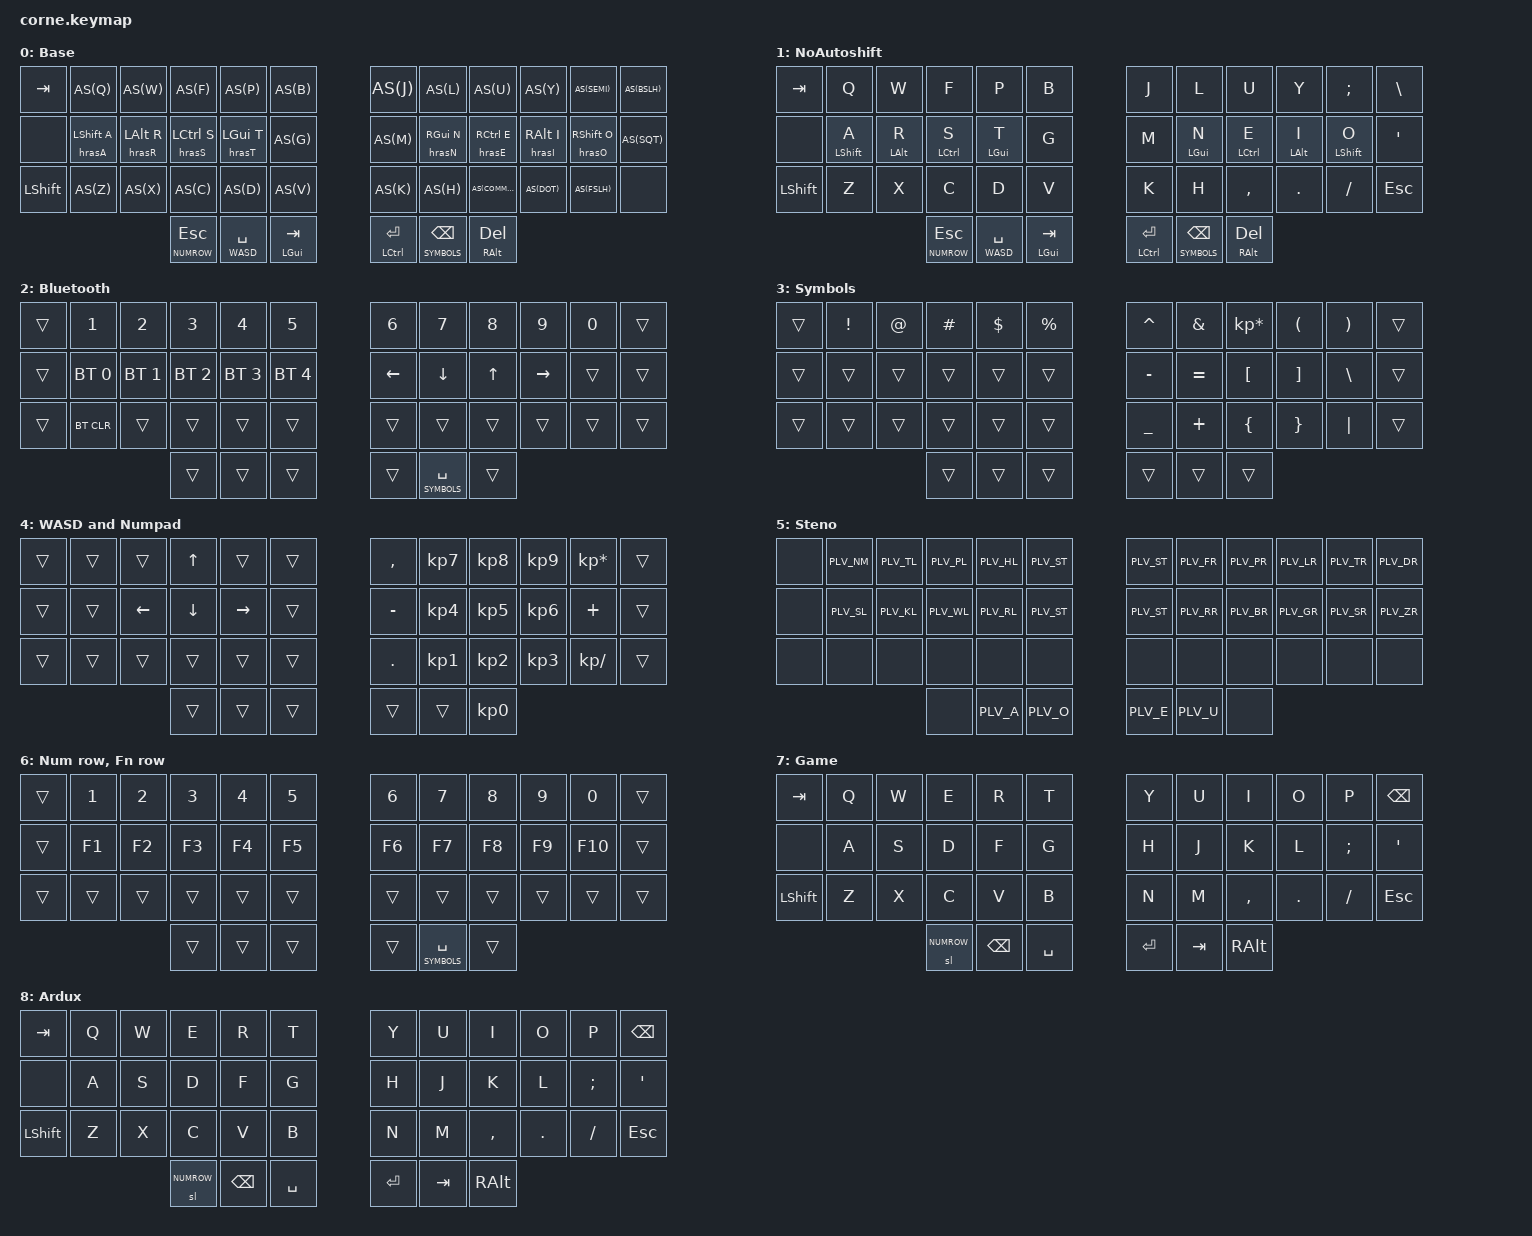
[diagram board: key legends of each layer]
/*
 * Copyright (c) 2020 The ZMK Contributors
 *
 * SPDX-License-Identifier: MIT
 */

#include <behaviors.dtsi>
#include <dt-bindings/zmk/keys.h>
#include <dt-bindings/zmk/bt.h>

#include "include/42.h"

#define KEYS_L LT0 LT1 LT2 LT3 LT4 LM0 LM1 LM2 LM3 LM4 LB0 LB1 LB2 LB3 LB4
#define KEYS_R RT0 RT1 RT2 RT3 RT4 RM0 RM1 RM2 RM3 RM4 RB0 RB1 RB2 RB3 RB4
#define THUMBS LH2 LH1 LH0 RH0 RH1 RH2   

#define DEFAULT 0
#define QWERTY 1
#define BT 2
#define SYMBOLS 3
#define WASD 4
#define STENO 5
#define NUMROW 6
#define GAME 7
#define ARDUX_LAYER 8

#define ALL_LAYERS_NO_ARDUX <0 1 2 3 4 5 6 7>
#define ARDUX_LAYERS <8 9 10 11 12 13 14 15 16 17>
#define QWERTY_CHAR_LAYERS <DEFAULT SYMBOLS NUMROW QWERTY>

#define AS(keycode) &as LS(keycode) keycode     // Autoshift Macro

#define combo_length 20

&lt { quick_tap_ms = <200>; };
&mt { quick_tap_ms = <200>; };

// TODO: This is loosely adapted from https://github.com/nickconway/zmk-config/blob/main/config/include/autoshift.dtsi
// The person who wrote this likes using macros. It's not yet clear to me if that's essential for how retro-tap is implemented.
// I ripped out using different times for different keys, but it's an interesting idea (was parameterized in the #define macro)
#define TAPPING_TERM 280 //200
#define TAPPING_TERM_RING 250
#define TAPPING_TERM_PINKY 300
#define QUICK_TAP_TERM 175 //300
#define REQUIRE_PRIOR_IDLE 150

/* How my janky home-row mods + autoshift work:
* Here we define two macros, for left and right HRMs (necessary because of setting hold-trigger-key-positions per-side). 
* These macros get instantiated into per-key behaviors in the behaviors section (necessary since the way autoshift is 
* implemented with retro-tap requires hardcoding the keycode, in a way that currently does not work with parameterization).
* We then use macros to define the specific keycodes, which are then used in the keymap.
* 
* Specifics on the HRM macros:
* - 'retro-tap' means that if you pass the hold-tap time but have not pressed a second key, the 'un-held' key is sent
* - voidyourwarranty2's ZMK patch (taken from nickconway) lets you specify a different custom action (with params) for when retro-tap activates
* - flavor = "balanced" means if you press multiple keys immediately, the combo will fire instead of waiting for tapping-term-ms
* - require-prior-idle-ms should minimize triggering if you're trying to roll through a HRM key
* - hold-trigger-key-positions should cause HRM to only activate if you press a key on the other half
* - hold-trigger-on-release means that hold behavior is triggered when the other key is *released*, not pressed, which should minimize false positives when quickly typing a key on one half then the other
* - quick-tap-ms lets you double-tap to jump to the tap behavior (maybe not necessary here?)
* - tapping-term-ms is intentionally long since we don't expect to hit it
*/
#define HRML(letter) \
    hras##letter: hras##letter { \
        compatible = "zmk,behavior-hold-tap"; \
        flavor = "balanced"; \
        tapping-term-ms = <TAPPING_TERM>; \
        quick-tap-ms = <QUICK_TAP_TERM>; \
        #binding-cells = <2>; \
        bindings = <&kp>, <&kp>; \
        retro-tap; \
        retro-tap-behavior = "key_press"; \
        retro-tap-param1 = <LS(letter)>; \
        require-prior-idle-ms = <REQUIRE_PRIOR_IDLE>; \
        hold-trigger-key-positions = <KEYS_R THUMBS>; \
        hold-trigger-on-release; \
    };

#define HRMR(letter) \
  hras##letter: hras##letter { \
      compatible = "zmk,behavior-hold-tap"; \
      flavor = "balanced"; \
      tapping-term-ms = <TAPPING_TERM>; \
      quick-tap-ms = <QUICK_TAP_TERM>; \
      #binding-cells = <2>; \
      bindings = <&kp>, <&kp>; \
      retro-tap; \
      retro-tap-behavior = "key_press"; \
      retro-tap-param1 = <LS(letter)>; \
      require-prior-idle-ms = <REQUIRE_PRIOR_IDLE>; \
      hold-trigger-key-positions = <KEYS_L THUMBS>; \
      hold-trigger-on-release; \
  };

/ {
  macros {
    ZMK_MACRO(spotlight_macro,
      wait-ms = <30>;
      tap-ms = <40>;
      bindings = <&macro_press &kp LGUI>
              , <&macro_tap &kp SPACE>
              , <&macro_release &kp LGUI>;
    )

    ZMK_MACRO(emdash_macro,
      wait-ms = <30>;
      tap-ms = <40>;
      bindings = <&macro_press &kp LSHIFT>
              , <&macro_press &kp LALT>
              , <&macro_tap &kp MINUS>
              , <&macro_release &kp LALT>
              , <&macro_release &kp LSHIFT>;
    )
  };

  combos {
    compatible = "zmk,combos";
    combo_tilde {
      timeout-ms = <combo_length>;
      key-positions = <13 14>;
      bindings = <&kp TILDE>;
      layers = QWERTY_CHAR_LAYERS;
    };
    combo_backtick {
      timeout-ms = <combo_length>;
      key-positions = <25 26>;
      bindings = <&kp GRAVE>;
      layers = QWERTY_CHAR_LAYERS;
    };
    combo_emdash {
      timeout-ms = <combo_length>;
      key-positions = <18 19 20>;
      bindings = <&emdash_macro>;
      layers = QWERTY_CHAR_LAYERS;
    };
    combo_hyphen {
      timeout-ms = <combo_length>;
      key-positions = <18 19>;
      bindings = <&kp MINUS>;
      layers = QWERTY_CHAR_LAYERS;
    };
    combo_underscore {
      timeout-ms = <combo_length>;
      key-positions = <30 31>;
      bindings = <&kp UNDER>;
      layers = QWERTY_CHAR_LAYERS;
    };
    combo_paren_open {
      timeout-ms = <combo_length>;
      key-positions = <8 9>;
      bindings = <&kp LPAR>;
      layers = QWERTY_CHAR_LAYERS;
    };
    combo_paren_close {
      timeout-ms = <combo_length>;
      key-positions = <9 10>;
      bindings = <&kp RPAR>;
      layers = QWERTY_CHAR_LAYERS;
    };
    combo_squarebracket_open {
      timeout-ms = <combo_length>;
      key-positions = <20 21>;
      bindings = <&kp LBKT>;
      layers = QWERTY_CHAR_LAYERS;
    };
    combo_squarebracket_close {
      timeout-ms = <combo_length>;
      key-positions = <21 22>;
      bindings = <&kp RBKT>;
      layers = QWERTY_CHAR_LAYERS;
    };
    combo_curlybracket_open {
      timeout-ms = <combo_length>;
      key-positions = <32 33>;
      bindings = <&kp LBRC>;
      layers = QWERTY_CHAR_LAYERS;
    };
    combo_curlybracket_close {
      timeout-ms = <combo_length>;
      key-positions = <33 34>;
      bindings = <&kp RBRC>;
      layers = QWERTY_CHAR_LAYERS;
    };
    combo_spotlight {
      timeout-ms = <50>;
      key-positions = <38 39>;
      bindings = <&spotlight_macro>;
      layers = QWERTY_CHAR_LAYERS;
    };
    combo_bt {
      timeout-ms = <50>;
      key-positions = <1 2 3 4>;
      bindings = <&sl BT>;
      layers = QWERTY_CHAR_LAYERS;
    };

    combo_esc {
      timeout-ms = <combo_length>;
      key-positions = <0 1>;
      bindings = <&kp ESC>;
      layers = QWERTY_CHAR_LAYERS;
    };
    combo_ardux {
      timeout-ms = <50>;
      key-positions = <25 26 27 28>;
      bindings = <&tog ARDUX_LAYER>;
    };
    combo_steno {
      timeout-ms = <50>;
      key-positions = <36 41>;
      bindings = <&tog STENO>;
    };
    combo_game {
      timeout-ms = <50>;
      key-positions = <1 13 25>;
      bindings = <&tog GAME>;
      layers = <DEFAULT GAME>;
    };
    combo_qwerty {
      timeout-ms = <50>;
      key-positions = <0 12 24>;
      bindings = <&tog QWERTY>;
      layers = <DEFAULT QWERTY>;
    };
    // combo_nextwindow {
    //   timeout-ms = <combo_length>;
    //   key-positions = <4 17>;
    //   bindings = <&nextwindow_macro>;
    // };
    // combo_previouswindow {
    //   timeout-ms = <combo_length>;
    //   key-positions = <3 16>;
    //   bindings = <&kp LGUI &kp LSHIFT &kp TAB>;
    // };
    // combo_previoustab {
    //   timeout-ms = <combo_length>;
    //   key-positions = <7 18>;
    //   bindings = <&kp LGUI &kp LSHIFT &kp LBKT>;
    // };
    // combo_nexttab {
    //   timeout-ms = <combo_length>;
    //   key-positions = <8 19>;
    //   bindings = <&kp LGUI &kp LSHIFT &kp RBKT>;
    // };     
  };

  behaviors {
    HRML(A)
    HRML(R)
    HRML(S)
    HRML(T)
    HRMR(N)
    HRMR(E)
    HRMR(I)
    HRMR(O)
    rpi: require_prior_idle {
      compatible = "zmk,behavior-hold-tap";
      #binding-cells = <2>;
      flavor = "tap-preferred";
      quick-tap-ms = <200>;
      tapping-term-ms = <200>;
      require-prior-idle-ms = <125>;
      bindings = <&kp>, <&kp>;
    };
    ctrl_caps: ctrl_caps {
      compatible = "zmk,behavior-tap-dance";
      #binding-cells = <0>;
      tapping-term-ms = <200>;
      bindings = <&kp LCTRL>, <&kp CAPS>;
    };
     as: auto_shift {
            compatible = "zmk,behavior-hold-tap";
            #binding-cells = <2>;
            tapping-term-ms = <170>;
            quick-tap-ms = <0>;
            flavor = "tap-preferred";
            bindings = <&kp>, <&kp>;
        };
  };

#define HRcA &hrasA LSHIFT A
#define HRcR &hrasR LALT R
#define HRcS &hrasS LCTRL S
#define HRcT &hrasT LGUI T
#define HRcN &hrasN RGUI N
#define HRcE &hrasE RCTRL E
#define HRcI &hrasI RALT I
#define HRcO &hrasO RSHIFT O

#define HRqA &hrasA LGUI A
#define HRqS &hrasR LCTRL S
#define HRqD &hrasS LALT D
#define HRqF &hrasT LSHIFT F
#define HRqJ &hrasN RGUI J
#define HRqK &hrasE RCTRL K
#define HRqL &hrasI RALT L
#define HRqSEMI &hrasO RSHIFT SEMI

  keymap {
    compatible = "zmk,keymap";

default_layer {
// -----------------------------------------------------------------------------------------
// |  TAB |  Q  |  W  |  F  |  P  |  B  |   |  J  |  L   |  U  |  Y  |  ;  |  \   |
// | none |  A  |  R  |  S  |  T  |  G  |   |  M  |  N   |  E  |  I  |  O  |  '   |
// | SHFT |  Z  |  X  |  C  |  D  |  V  |   |  K  |  H   |  ,  |  .  |  /  | ESC  |
// | Num and FN | Space / WASD | TAB / LGUI |   | Return / LCTRL  | Backspace / Symbols  | Delete / RALT |
      display-name = "Base";
      bindings = <
   &kp TAB   AS(Q) AS(W) AS(F) AS(P) AS(B)   AS(J) AS(L)  AS(U)     AS(Y)   AS(SEMI)    AS(BSLH)
   /*&ctrl_caps*/ &none HRcA HRcR HRcS HRcT AS(G)   AS(M) HRcN HRcE HRcI HRcO AS(SQT)
   &kp LSHFT AS(Z) AS(X) AS(C) AS(D) AS(V)   AS(K) AS(H)  AS(COMMA) AS(DOT) AS(FSLH) /*&kp ESC*/ &none
      &lt NUMROW ESC &lt WASD SPACE &rpi LGUI TAB   &rpi LCTRL RET &lt SYMBOLS BSPC &rpi RALT DEL
      >;
    };


no_autoshift_layer {
// -----------------------------------------------------------------------------------------
// |  TAB |  Q  |  W  |  F  |  P  |  B  |   |  J  |  L   |  U  |  Y  |  ;  |  \   |
// | none |  A  |  R  |  S  |  T  |  G  |   |  M  |  N   |  E  |  I  |  O  |  '   |
// | SHFT |  Z  |  X  |  C  |  D  |  V  |   |  K  |  H   |  ,  |  .  |  /  | ESC  |
// | Num and FN | Space / WASD | TAB / LGUI |   | Return / LCTRL  | Backspace / Symbols  | Delete / RALT |
      display-name = "NoAutoshift";
      bindings = <
   &kp TAB   &kp Q   &kp W   &kp F   &kp P   &kp B   &kp J   &kp L   &kp U   &kp Y   &kp SEMI   &kp BSLH
   /*&ctrl_caps*/ &none &rpi LSHIFT A &rpi LALT R &rpi LCTRL S &rpi LGUI T &kp G &kp M &rpi LGUI N &rpi LCTRL E &rpi LALT I &rpi LSHIFT O &kp SQT
   &kp LSHFT &kp Z   &kp X   &kp C   &kp D   &kp V   &kp K   &kp H   &kp COMMA   &kp DOT   &kp FSLH   &kp ESC
      &lt NUMROW ESC &lt WASD SPACE &rpi LGUI TAB   &rpi LCTRL RET &lt SYMBOLS BSPC &rpi RALT DEL
      >;
    };

    // qwerty_layer {
    //   // -----------------------------------------------------------------------------------------
    //   // |  TAB |  Q  |  W  |  E  |  R  |  T  |   |  Y  |  U   |  I  |  O  |  P  |  \   |
    //   // | none |  A  |  S  |  D  |  F  |  G  |   |  H  |  J   |  K  |  L  |  ;  |  '   |
    //   // | SHFT |  Z  |  X  |  C  |  V  |  B  |   |  N  |  M   |  ,  |  .  |  /  | ESC  |
    //   // | Escape / Num row /  | Space / WASD | TAB / LGUI |   | Return / LCTRL  | Backspace / Symbols  | Delete / RALT |
    //         display-name = "QWERTY";
    //         bindings = <
    //      &kp TAB   AS(Q) AS(W) AS(E) AS(R) AS(T)   AS(Y) AS(U)  AS(I)     AS(O)   AS(P)    AS(BSLH)
    //      /*&ctrl_caps*/ &none HRqA HRqS HRqD HRqF AS(G)   AS(H) HRqJ  HRqK HRqL HRqSEMI AS(SQT)
    //      &kp LSHFT AS(Z) AS(X) AS(C) AS(V) AS(B)   AS(N) AS(M)  AS(COMMA) AS(DOT) AS(FSLH) &kp ESC
    //         &lt NUMROW ESC &lt WASD SPACE &rpi LGUI TAB   &rpi LCTRL RET &lt SYMBOLS BSPC &rpi RALT DEL
    //         >;
    //       };

    bt_layer {
// -----------------------------------------------------------------------------------------
// |  TAB |  1  |  2  |  3  |  4  |  5  |   |  6  |  7  |  8  |  9  |  0  | BKSP |
// | BTCLR| BT1 | BT2 | BT3 | BT4 | BT5 |   | LFT | DWN |  UP | RGT |     |      |
// | SHFT |     |     |     |     |     |   |     |     |     |     |     |      |
//                    | GUI |     | SPC |   | ENT |     | ALT |
      display-name = "Bluetooth";
      bindings = <
   &trans    &kp N1       &kp N2       &kp N3       &kp N4       &kp N5         &kp N6   &kp N7   &kp N8 &kp N9    &kp N0 &trans
   &trans &bt BT_SEL 0 &bt BT_SEL 1 &bt BT_SEL 2 &bt BT_SEL 3 &bt BT_SEL 4   &kp LEFT &kp DOWN &kp UP &kp RIGHT &trans &trans
   &trans &bt BT_CLR         &trans       &trans       &trans       &trans         &trans   &trans   &trans &trans    &trans &trans
            &trans     &trans       &trans      &trans  &lt SYMBOLS SPACE   &trans
      >;
    };

    sym_layer {
// -----------------------------------------------------------------------------------------
// |  TAB |  !  |  @  |  #  |  $  |  %  |   |  ^  |  &  |  *  |  (  |  )  | BKSP |
// | CTRL |     |     |     |     |     |   |  -  |  =  |  [  |  ]  |  \  |  `   |
// | SHFT |     |     |     |     |     |   |  _  |  +  |  {  |  }  | "|" |  ~   |
      display-name = "Symbols";
      bindings = <
   &trans  &kp EXCL &kp AT &kp HASH &kp DLLR &kp PRCNT   &kp CARET &kp AMPS  &kp KP_MULTIPLY &kp LPAR &kp RPAR &trans
   &trans &trans   &trans &trans   &trans   &trans      &kp MINUS &kp EQUAL &kp LBKT        &kp RBKT &kp BSLH /*&kp GRAVE*/ &trans
   &trans &trans   &trans &trans   &trans   &trans      &kp UNDER &kp PLUS  &kp LBRC        &kp RBRC &kp PIPE /*&kp TILDE*/ &trans
               &trans &trans   &trans   &trans   &trans    &trans
      >;
    };
  wasd_layer {
// -----------------------------------------------------------------------------------------
// |  TAB |     |  W  |     |     |     |   |  ,  |  7  |  8  |  9  |  /  |     |
// | CTRL |  A  |  S  |  D  |     |     |   |  -  |  4  |  5  |  6  |  *  |      |
// | SHFT |     |     |     |     |     |   |  .  |  1 |  2  |  3  |  +  |      |
//                    |     |     |     |   |     |     |    |
      display-name = "WASD and Numpad";
      bindings = <
   &trans &trans &trans &kp UP &trans &trans   &kp COMMA &kp KP_N7  &kp KP_N8 &kp KP_N9 &kp KP_MULTIPLY &trans
&trans &trans &kp LEFT  &kp DOWN &kp RIGHT   &trans     &kp MINUS &kp KP_N4 &kp KP_N5  &kp KP_N6 &kp PLUS &trans
   &trans &trans   &trans &trans   &trans   &trans      &kp DOT &kp KP_N1  &kp KP_N2  &kp KP_N3 &kp KP_DIVIDE &trans
               &trans &trans   &trans   &trans   &trans    &kp KP_N0
      >;
    };

//    -----------------------------------------------------------------------------------------
// |     |  #  |  T  |  P  |  H  |  *  |   |  *  |  F  |  P  |  L  |  T  |  D  |
// |     |  S  |  K  |  W  |  R  |  *  |   |  *  |  R  |  B  |  G  |  S  |  Z  |
// |     |     |     |     |  A  |  O  |   |  E  |  U  |     |     |     |    |
//   

    steno_layer {
      display-name = "Steno";
      bindings = <
&none &kp PLV_NM &kp PLV_TL &kp PLV_PL &kp PLV_HL &kp PLV_ST   &kp PLV_ST &kp PLV_FR &kp PLV_PR &kp PLV_LR &kp PLV_TR &kp PLV_DR
&none &kp PLV_SL &kp PLV_KL &kp PLV_WL &kp PLV_RL &kp PLV_ST   &kp PLV_ST &kp PLV_RR &kp PLV_BR &kp PLV_GR &kp PLV_SR &kp PLV_ZR
&none &none &none &none &none &none   &none &none &none &none &none &none
               &none &kp PLV_A   &kp PLV_O   &kp PLV_E   &kp PLV_U    &none
      >;
    };

    function_layer {
      display-name = "Num row, Fn row";
      bindings = <
         &trans    &kp N1       &kp N2       &kp N3       &kp N4       &kp N5         &kp N6   &kp N7   &kp N8 &kp N9    &kp N0 &trans
  /*&kp F12*/ &trans &kp F1 &kp F2 &kp F3 &kp F4 &kp F5			&kp F6 &kp F7 &kp F8 &kp F9 &kp F10 &trans
   &trans  &trans       &trans       &trans       &trans       &trans         &trans   &trans   &trans &trans    &trans &trans
            &trans     &trans       &trans      &trans  &lt SYMBOLS SPACE   &trans
      >;
    };

    game_layer {
      display-name = "Game";
      bindings = <
          &kp TAB   &kp Q &kp W &kp E &kp R &kp T   &kp Y &kp U  &kp I     &kp O   &kp P    &kp BSPC
   /*&ctrl_caps*/ &none &kp A &kp S &kp D &kp F &kp G   &kp H &kp J  &kp K     &kp L   &kp SEMI &kp SQT
   &kp LSHFT &kp Z &kp X &kp C &kp V &kp B   &kp N &kp M  &kp COMMA &kp DOT &kp FSLH &kp ESC
      &sl NUMROW &kp BSPC &kp SPACE   &kp RET &kp TAB &kp RALT
      >;
    };

    ardux_layer {
      display-name = "Ardux";
      bindings = <
          &kp TAB   &kp Q &kp W &kp E &kp R &kp T   &kp Y &kp U  &kp I     &kp O   &kp P    &kp BSPC
   /*&ctrl_caps*/ &none &kp A &kp S &kp D &kp F &kp G   &kp H &kp J  &kp K     &kp L   &kp SEMI &kp SQT
   &kp LSHFT &kp Z &kp X &kp C &kp V &kp B   &kp N &kp M  &kp COMMA &kp DOT &kp FSLH &kp ESC
      &sl NUMROW &kp BSPC &kp SPACE   &kp RET &kp TAB &kp RALT
      >;
    };
  };
};

// Setup custom double Ardux

#define KEY_L_A 4
#define KEY_L_R 3
#define KEY_L_T 2
#define KEY_L_S 1
#define KEY_L_E 16
#define KEY_L_Y 15
#define KEY_L_I 14
#define KEY_L_O 13

#define KEY_R_A 7
#define KEY_R_R 8
#define KEY_R_T 9
#define KEY_R_S 10
#define KEY_R_E 19
#define KEY_R_Y 20
#define KEY_R_I 21
#define KEY_R_O 22

// Bottom row, thumb cluster (12 + 6)
#define TRAILING_NONES NONE(0, 1, 8)

// Finally include Ardux itself
#include "include/ardux.dtsi"
